# GD32E502 register map
File version: 1.0
CPU: CM33 r0p4, little endian, MPU, FPU, 4 interrupt priority bits
Registers are 32-bit, read-write, reset 0x0 unless marked. A register's access mark holds for its fields unless they carry their own. Offsets are from the block's base; [hi:lo] are bit positions; 'fields as' and 'values as' point back to an identical list.

## FMC
Base 0x40022000
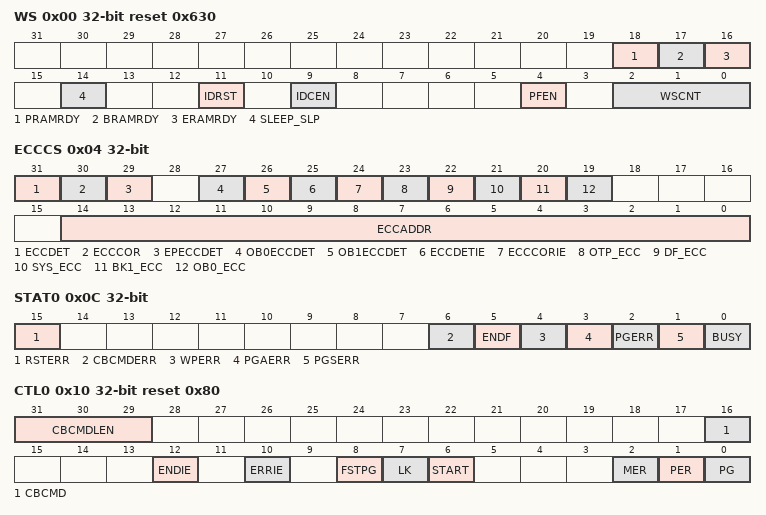
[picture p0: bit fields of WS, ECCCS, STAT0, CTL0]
0x00 WS access per field reset 0x630 — wait state register
  [18] PRAMRDY ro — Fast program SRAM ready flag
  [17] BRAMRDY ro — Basic SRAM ready flag
  [16] ERAMRDY ro — EEPROM SRAM ready flag
  [14] SLEEP_SLP rw — Flash goto sleep mode or power-down mode when MCU enters deepsleep mode
  [11] IDRST rw — Cache reset
  [9] IDCEN rw — Cache enable
  [4] PFEN rw — Pre-fetch enable
  [2:0] WSCNT rw — wait state counter register
0x04 ECCCS access per field — ECC control and status register
  [31] ECCDET ro — Two bit errors detect flag.
  [30] ECCCOR ro — One bit error detected and correct flag
  [29] EPECCDET ro — EEPROM two bit errors detect flag
  [27] OB0ECCDET ro — Option bytes two bit errors detect flag
  [26] OB1ECCDET ro — Option bytes 1 two bit errors detect flag
  [25] ECCDETIE ro — Two bit errors detect interrupt enable
  [24] ECCCORIE rw — One bit error correct interrupt enable
  [23] OTP_ECC ro — ECC bit error is detected in OTP
  [22] DF_ECC ro — ECC bit error is detected in data flash
  [21] SYS_ECC ro — Cache enable
  [20] BK1_ECC ro — ECC bit error is detected in bank 1
  [19] OB0_ECC ro — An ECC bit error is detected in option bytes 0
  [14:0] ECCADDR ro — The offset address of double word where an ECC error is detected.
0x08 KEY0 wo — Unlock key register0
  [31:0] KEY — FMC_CTL unlock register
0x0C STAT0 access per field — Status register 0
  [15] RSTERR rw — voltage is below 2.8V or a system reset occurs
  [6] CBCMDERR rw — The checked area by the check blank command is all 0xFF or not.
  [5] ENDF rw — End of operation flag bit
  [4] WPERR rw — Erase/Program protection error flag bit
  [3] PGAERR rw — Program alignment error flag bit
  [2] PGERR rw — Program error flag bit
  [1] PGSERR rw — Program sequence error flag bit.
  [0] BUSY ro — The flash is busy bit
0x10 CTL0 reset 0x80 — Control register 0
  [31:29] CBCMDLEN — CBCMD read length 2^(CBCMDLEN)
  [16] CBCMD — The command to check the selected area is blank or not.
  [12] ENDIE — End of operation interrupt enable bit
  [10] ERRIE — Error interrupt enable bit
  [8] FSTPG — Main flash fast program command bit
  [7] LK — FMC_CTL lock bit
  [6] START — Send erase command to FMC bit
  [2] MER — Main flash mass erase for bank0 command bit
  [1] PER — Main flash page erase for bank0 command bit
  [0] PG — Main flash program for bank0 command bit
0x14 ADDR0 wo — Address register 0
  [31:0] ADDR — Flash erase/program command address bits
0x44 OBKEY wo — Option byte unlock key register
  [31:0] OBKEY — FMC_ CTL1 option bytes operation unlock register
0x48 KEY1 wo — Unlock key register 1
  [31:0] KEY — FMC_CTL1 unlock register
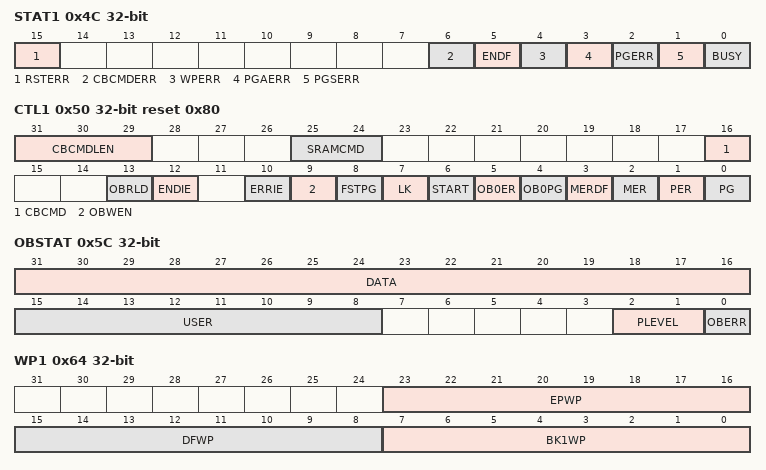
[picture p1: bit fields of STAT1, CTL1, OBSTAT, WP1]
0x4C STAT1 access per field — Status register 1
  fields as STAT0
0x50 CTL1 reset 0x80 — Control register 1
  [31:29] CBCMDLEN — CBCMD read length 2^(CBCMDLEN)
  [25:24] SRAMCMD — Shared SRAM command
  [16] CBCMD — The command to check the selected area is blank or not.
  [13] OBRLD — Option byte reload bit
  [12] ENDIE — End of operation interrupt enable bit
  [10] ERRIE — Error interrupt enable bit
  [9] OBWEN — Option byte erase/program enable bit
  [8] FSTPG — Main flash fast program command bit
  [7] LK — FMC_CTL1 lock bit
  [6] START — Send erase command to FMC bit
  [5] OB0ER — Option bytes 0 erase command bit
  [4] OB0PG — Option bytes 0 program command bit
  [3] MERDF — Data flash mass erase command bit
  [2] MER — Main flash mass erase for bank1 command bit
  [1] PER — Main flash page erase for bank1 command bit
  [0] PG — Main flash program for bank1 command bit
0x54 ADDR1 wo — Address register 1
  [31:0] ADDR — Flash erase/program command address bits
0x58 EPCNT ro — EP counter register
  [31:0] EPCNT — Record the EEPROM erase counter
0x5C OBSTAT ro — Option byte control register
  [31:16] DATA — Store DATA[15:0] of option bytes block after system reset
  [15:8] USER — Store USER of option bytes block after system reset
  [2:1] PLEVEL — Option bytes security protection level
  [0] OBERR — Option bytes read error bit
0x60 WP0 ro — Erase/Program Protection register 0
  [31:0] BK0WP — Store WP[31:0] of option bytes block after system reset
0x64 WP1 ro — Erase/Program Protection register 1
  [23:16] EPWP — Store EEPROM WP of option bytes block after system reset.
  [15:8] DFWP — Store Data Flash WP of option bytes block after system reset.
  [7:0] BK1WP — Store bank 1 WP of option bytes block after system reset.
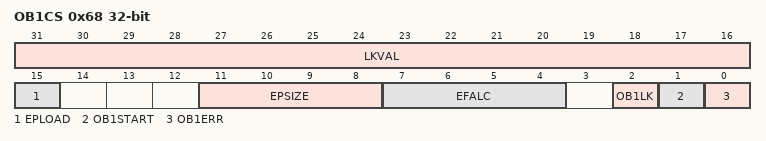
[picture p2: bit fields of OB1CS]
0x68 OB1CS access per field — Option byte1 control and status register
  [31:16] LKVAL rw — Load OB1_LK_VALUE of option byte 1 after reset
  [15] EPLOAD rw — Load EPLOAD of option byte 1 after reset
  [11:8] EPSIZE rw — Load EPSIZE of option byte 1 after reset
  [7:4] EFALC rw — Load EFALC of option byte 1 after reset
  [2] OB1LK ro — When OB1_LK_VALUE is 0x33CC, the OB1LK bit will be set. If OB1LK is 1, the FMC_OB1CS register cannot be configured anymore
  [1] OB1START rw — Send option byte 1 change command to FMC.
  [0] OB1ERR ro — Option bytes 1 read error bit.
0x100 PID ro — Product ID register
  [31:0] PID — Product reserved ID code register
